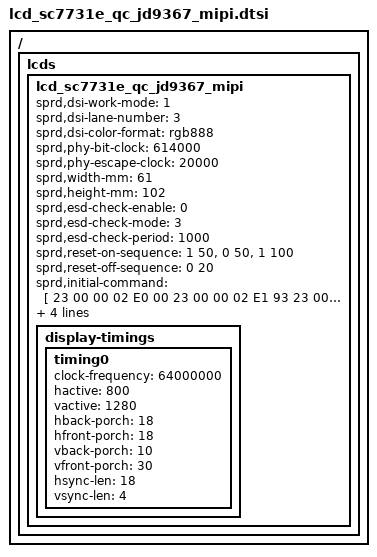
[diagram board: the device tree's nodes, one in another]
/ { lcds {
	lcd_sc7731e_qc_jd9367_mipi: lcd_sc7731e_qc_jd9367_mipi {

		sprd,dsi-work-mode = <1>;
		sprd,dsi-lane-number = <3>;
		sprd,dsi-color-format = "rgb888";

		sprd,phy-bit-clock = <614000>;
		sprd,phy-escape-clock = <20000>;

		sprd,width-mm = <61>;
		sprd,height-mm = <102>;

		sprd,esd-check-enable = <0>;
		sprd,esd-check-mode = <3>;
		sprd,esd-check-period = <1000>;
		/*sprd,esd-check-register = <0x0A>;*/
		/*sprd,esd-check-value = <0x9C>;*/

		sprd,reset-on-sequence = <1 50>, <0 50>, <1 100>;
		sprd,reset-off-sequence = <0 20>;

		sprd,initial-command = [
			  23  00  00  02  E0  00

//--- PASSWORD  ----//
			  23  00  00  02  E1  93
			  23  00  00  02  E2  65
			  23  00  00  02  E3  F8

			  23  00  00  02  70  10	//DC0DC1
			  23  00  00  02  71  13	//DC2DC3
			  23  00  00  02  72  06	//DC7
			  23  00  00  02  80  02
			  23  00  00  02  E6  02
			  23  00  00  02  E7  02

//--- Page1  ----//
			  23  00  00  02  E0  01
//Set VCOM
			  23  00  00  02  01  70


//			  23  00  00  02  4A  30  Он╝В─Б╩й

			  23  00  00  02  18  D7
			  23  00  00  02  19  05

			  23  00  00  02  1B  D7  //VGMN=0
			  23  00  00  02  1C  05 
             
			  23  00  00  02  1F  79
			  23  00  00  02  20  2D	
			  23  00  00  02  21  2D

			  23  00  00  02  26  F1	//VDDD from IOVCC
			  23  00  00  02  37  09	//SS=1BGR=1
			  23  00  00  02  38  04	//JDT=100 column inversion
			  23  00  00  02  3C  78	//SET EQ3 for TE_H
			  23  00  00  02  40  06	//RSO=
			  23  00  00  02  41  A0	//LN=640->1280 line

			  23  00  00  02  55  01	//DCDCM=0001 JD PWR_IC

			  23  00  00  02  57  A9
			  23  00  00  02  59  2A	//VCL = -2.7V
			  23  00  00  02  5A  37	//VGH = 19V

//--- Gamma  ----//
			  23  00  00  02  5D  70
			  23  00  00  02  5E  50
			  23  00  00  02  5F  3F
			  23  00  00  02  60  31
			  23  00  00  02  61  2D
			  23  00  00  02  62  1D
			  23  00  00  02  63  22
			  23  00  00  02  64  0C
			  23  00  00  02  65  25
			  23  00  00  02  66  24
			  23  00  00  02  67  24
			  23  00  00  02  68  41
			  23  00  00  02  69  2F
			  23  00  00  02  6A  36
			  23  00  00  02  6B  28
			  23  00  00  02  6C  26
			  23  00  00  02  6D  1C
			  23  00  00  02  6E  08
			  23  00  00  02  6F  02
			  23  00  00  02  70  70
			  23  00  00  02  71  50
			  23  00  00  02  72  3F
			  23  00  00  02  73  31
			  23  00  00  02  74  2D
			  23  00  00  02  75  1D
			  23  00  00  02  76  22
			  23  00  00  02  77  0C
			  23  00  00  02  78  25
			  23  00  00  02  79  24
			  23  00  00  02  7A  24
			  23  00  00  02  7B  41
			  23  00  00  02  7C  2F
			  23  00  00  02  7D  36
			  23  00  00  02  7E  28
			  23  00  00  02  7F  26
			  23  00  00  02  80  1C
			  23  00  00  02  81  08
			  23  00  00  02  82  02

//Page2 for GIP
			  23  00  00  02  E0  02

//GIP_L Pin mapping
			  23  00  00  02  00  00
			  23  00  00  02  01  04  
			  23  00  00  02  02  06
			  23  00  00  02  03  08
			  23  00  00  02  04  0A
			  23  00  00  02  05  0C
			  23  00  00  02  06  0E
			  23  00  00  02  07  17
			  23  00  00  02  08  18
			  23  00  00  02  09  1F
			  23  00  00  02  0A  10
			  23  00  00  02  0B  1F
			  23  00  00  02  0C  1F
			  23  00  00  02  0D  1F
			  23  00  00  02  0E  1F
			  23  00  00  02  0F  1F
			  23  00  00  02  10  1F
			  23  00  00  02  11  1F
			  23  00  00  02  12  1F
			  23  00  00  02  13  12
			  23  00  00  02  14  1F
			  23  00  00  02  15  1F

//GIP_R Pin mapping
			  23  00  00  02  16  01
			  23  00  00  02  17  05
			  23  00  00  02  18  07
			  23  00  00  02  19  09
			  23  00  00  02  1A  0B
			  23  00  00  02  1B  0D
			  23  00  00  02  1C  0F
			  23  00  00  02  1D  17
			  23  00  00  02  1E  18
			  23  00  00  02  1F  1F
			  23  00  00  02  20  11
			  23  00  00  02  21  1F
			  23  00  00  02  22  1F
			  23  00  00  02  23  1F
			  23  00  00  02  24  1F
			  23  00  00  02  25  1F
			  23  00  00  02  26  1F
			  23  00  00  02  27  1F
			  23  00  00  02  28  1F
			  23  00  00  02  29  13  
			  23  00  00  02  2A  1F
			  23  00  00  02  2B  1F

//GIP Timing
			  23  00  00  02  58  10 
			  23  00  00  02  5C  07 
			  23  00  00  02  5D  30 
			  23  00  00  02  5E  00 
			  23  00  00  02  5F  00 
			  23  00  00  02  60  30 
			  23  00  00  02  61  03 
			  23  00  00  02  62  04 
			  23  00  00  02  63  03 
			  23  00  00  02  64  73 
			  23  00  00  02  65  75 
			  23  00  00  02  66  0D 
			  23  00  00  02  67  B3 
			  23  00  00  02  68  09 
			  23  00  00  02  69  06 
			  23  00  00  02  6A  73 
			  23  00  00  02  6B  04 
			  23  00  00  02  75  BC   
			  23  00  00  02  77  0D 
			  23  00  00  02  78  2C 
			  23  00  00  02  79  00 
			  23  00  00  02  E0  04	//DC7
			  23  00  00  02  2B  2B
			  23  00  00  02  2E  44
			  23  00  00  02  2D  03
			  23  00  00  02  09  10
			  23  00  00  02  E0  00
				13 78 00 01 11
				13 64 00 01 29
			];
		sprd,sleep-in-command = [
			23 1A  00  02  E0  00
			13 0A 00 01 28
			13 78 00 01 10
			];
		sprd,sleep-out-command = [
			13 78 00 01 11
			13 64 00 01 29
			];

		display-timings {
			timing0 {
			clock-frequency = <64000000>;
			hactive = <800>;
			vactive = <1280>;
			hback-porch = <18>;
			hfront-porch = <18>;
			vback-porch = <10>;
			vfront-porch = <30>;
			hsync-len = <18>;
			vsync-len = <4>;
			};
		};
	};
};};

